# HDSC_HC32M120J6TB register map
Vendor: HDSC Co.,Ltd.; Series: ARMCM0P; File version: 1.0
CPU: CM0P r0p1, little endian, no MPU, no FPU, 4 interrupt priority bits
Registers are 32-bit, read-write, reset 0x0 unless marked. A register's access mark holds for its fields unless they carry their own. Offsets are from the block's base; [hi:lo] are bit positions; {n}, {i} and the like mark numbered series; 'fields as' and 'values as' point back to an identical list.

## ICG
Base 0x000000C0
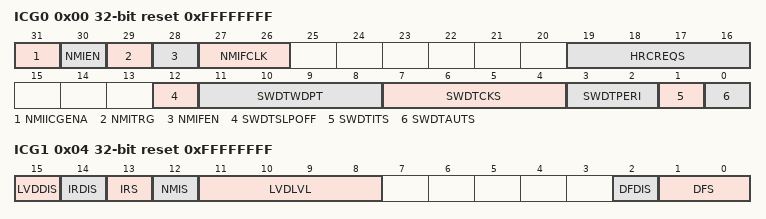
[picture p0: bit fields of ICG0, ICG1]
0x00 ICG0 ro reset 0xFFFFFFFF
  [31] NMIICGENA, [30] NMIEN, [29] NMITRG, [28] NMIFEN, [27:26] NMIFCLK, [19:16] HRCREQS, [12] SWDTSLPOFF, [11:8] SWDTWDPT, [7:4] SWDTCKS, [3:2] SWDTPERI, [1] SWDTITS, [0] SWDTAUTS
0x04 ICG1 ro reset 0xFFFFFFFF
  [15] LVDDIS, [14] IRDIS, [13] IRS, [12] NMIS, [11:8] LVDLVL, [2] DFDIS, [1:0] DFS
{0x0+4i} ICG{i} ro reset 0xFFFFFFFF (reset mask 0x0) (i=2..7)

## INTC
Base 0x40011000
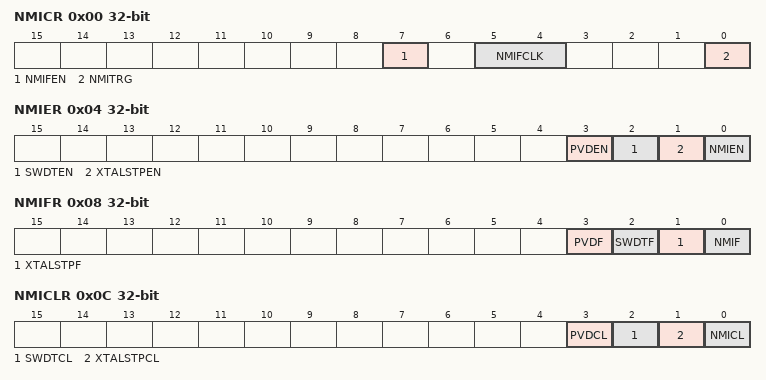
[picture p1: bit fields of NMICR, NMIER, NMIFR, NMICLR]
0x00 NMICR
  [7] NMIFEN, [5:4] NMIFCLK, [0] NMITRG
0x04 NMIER
  [3] PVDEN, [2] SWDTEN, [1] XTALSTPEN, [0] NMIEN
0x08 NMIFR ro
  [3] PVDF, [2] SWDTF, [1] XTALSTPF, [0] NMIF
0x0C NMICLR
  [3] PVDCL, [2] SWDTCL, [1] XTALSTPCL, [0] NMICL
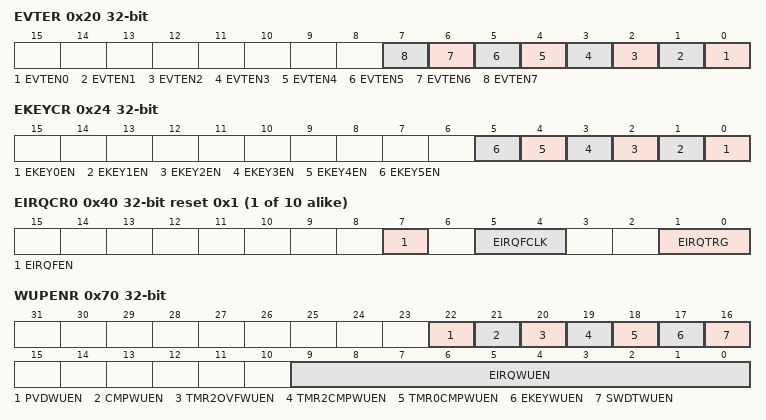
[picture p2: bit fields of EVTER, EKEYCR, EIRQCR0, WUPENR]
0x20 EVTER
  [n] EVTEN{n} (n=0..7)
0x24 EKEYCR
  [n] EKEY{n}EN (n=0..5)
0x3C FPRCR
  [7:0] FPRC
{0x40+4i} EIRQCR{i} reset 0x1 (i=0..9)
  [7] EIRQFEN, [5:4] EIRQFCLK, [1:0] EIRQTRG
0x70 WUPENR
  [22] PVDWUEN, [21] CMPWUEN, [20] TMR2OVFWUEN, [19] TMR2CMPWUEN, [18] TMR0CMPWUEN, [17] EKEYWUEN, [16] SWDTWUEN, [9:0] EIRQWUEN
0x74 EIRQFR
  [9:0] EIRQF
0x78 EIRQCLR
  [9:0] EIRQCL
{0x80+4i} ISELAR{i} (i=8..23)
  [3:0] ISEL
{0x80+4i} ISELBR{i} (i=24..31)
  [15:1] ISEL

## PORT
Base 0x40013800
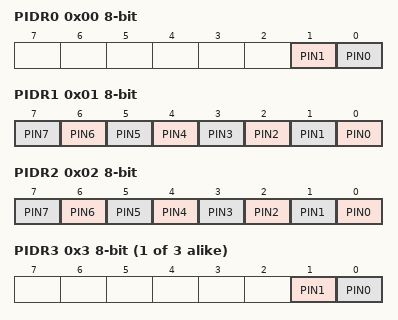
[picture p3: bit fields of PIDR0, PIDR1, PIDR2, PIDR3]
0x00 PIDR0 8-bit ro
  [1] PIN1, [0] PIN0
0x01 PIDR1 8-bit ro
  [n] PIN{n} (n=0..7)
0x02 PIDR2 8-bit ro
  [n] PIN{n} (n=0..7)
{0x0+i} PIDR{i} 8-bit ro (i=3..5)
  [1] PIN1, [0] PIN0
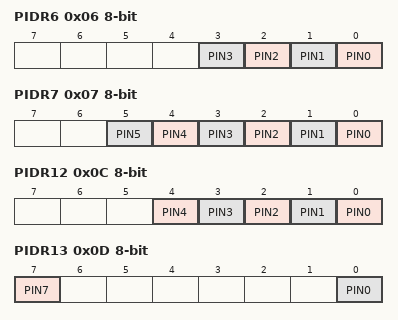
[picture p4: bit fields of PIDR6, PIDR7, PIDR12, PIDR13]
0x06 PIDR6 8-bit ro
  [n] PIN{n} (n=0..3)
0x07 PIDR7 8-bit ro
  [n] PIN{n} (n=0..5)
0x0C PIDR12 8-bit ro
  [n] PIN{n} (n=0..4)
0x0D PIDR13 8-bit ro
  [7] PIN7, [0] PIN0
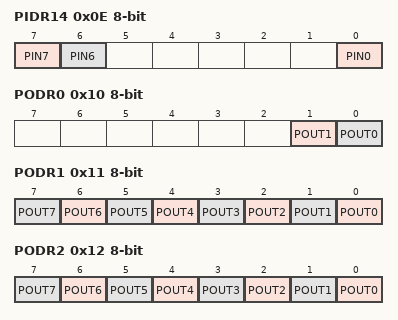
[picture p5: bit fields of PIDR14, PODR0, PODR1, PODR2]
0x0E PIDR14 8-bit ro
  [7] PIN7, [6] PIN6, [0] PIN0
0x10 PODR0 8-bit
  [1] POUT1, [0] POUT0
0x11 PODR1 8-bit
  [n] POUT{n} (n=0..7)
0x12 PODR2 8-bit
  [n] POUT{n} (n=0..7)
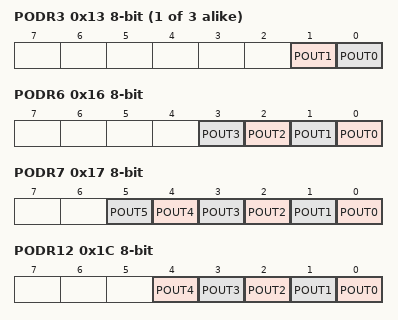
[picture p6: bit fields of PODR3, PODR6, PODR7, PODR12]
{0x10+i} PODR{i} 8-bit (i=3..5)
  [1] POUT1, [0] POUT0
0x16 PODR6 8-bit
  [n] POUT{n} (n=0..3)
0x17 PODR7 8-bit
  [n] POUT{n} (n=0..5)
0x1C PODR12 8-bit
  [n] POUT{n} (n=0..4)
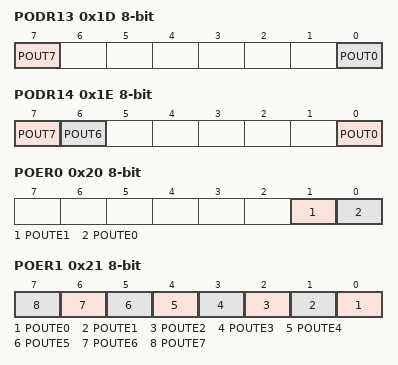
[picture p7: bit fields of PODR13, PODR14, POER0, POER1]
0x1D PODR13 8-bit
  [7] POUT7, [0] POUT0
0x1E PODR14 8-bit
  [7] POUT7, [6] POUT6, [0] POUT0
0x20 POER0 8-bit
  [1] POUTE1, [0] POUTE0
0x21 POER1 8-bit
  [n] POUTE{n} (n=0..7)
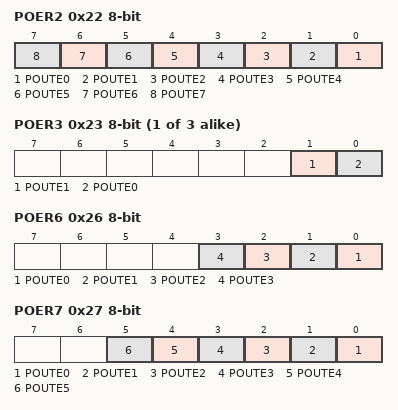
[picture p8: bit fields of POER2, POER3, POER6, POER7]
0x22 POER2 8-bit
  [n] POUTE{n} (n=0..7)
{0x20+i} POER{i} 8-bit (i=3..5)
  [1] POUTE1, [0] POUTE0
0x26 POER6 8-bit
  [n] POUTE{n} (n=0..3)
0x27 POER7 8-bit
  [n] POUTE{n} (n=0..5)
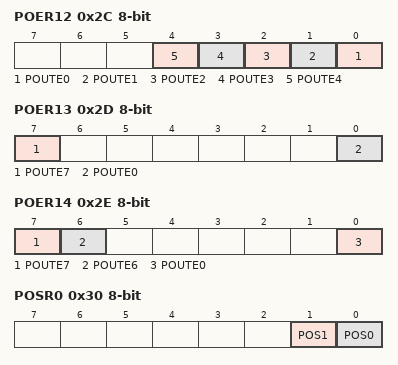
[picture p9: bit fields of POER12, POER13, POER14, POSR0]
0x2C POER12 8-bit
  [n] POUTE{n} (n=0..4)
0x2D POER13 8-bit
  [7] POUTE7, [0] POUTE0
0x2E POER14 8-bit
  [7] POUTE7, [6] POUTE6, [0] POUTE0
0x30 POSR0 8-bit wo
  [1] POS1, [0] POS0
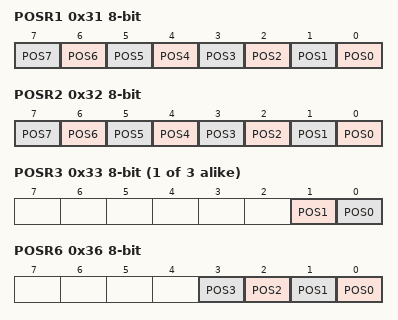
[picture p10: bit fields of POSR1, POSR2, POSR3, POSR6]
0x31 POSR1 8-bit wo
  [n] POS{n} (n=0..7)
0x32 POSR2 8-bit wo
  [n] POS{n} (n=0..7)
{0x30+i} POSR{i} 8-bit wo (i=3..5)
  [1] POS1, [0] POS0
0x36 POSR6 8-bit wo
  [n] POS{n} (n=0..3)
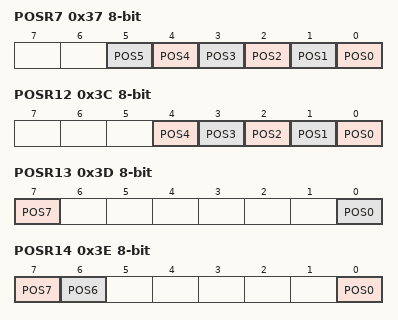
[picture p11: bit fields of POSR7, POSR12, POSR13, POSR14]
0x37 POSR7 8-bit wo
  [n] POS{n} (n=0..5)
0x3C POSR12 8-bit wo
  [n] POS{n} (n=0..4)
0x3D POSR13 8-bit wo
  [7] POS7, [0] POS0
0x3E POSR14 8-bit wo
  [7] POS7, [6] POS6, [0] POS0
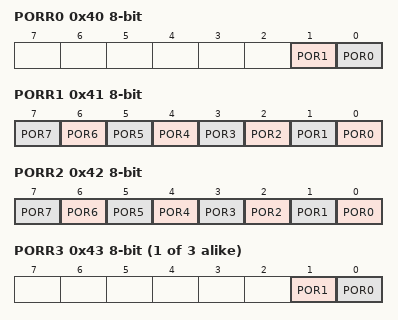
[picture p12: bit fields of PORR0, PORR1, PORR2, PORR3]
0x40 PORR0 8-bit wo
  [1] POR1, [0] POR0
0x41 PORR1 8-bit wo
  [n] POR{n} (n=0..7)
0x42 PORR2 8-bit wo
  [n] POR{n} (n=0..7)
{0x40+i} PORR{i} 8-bit wo (i=3..5)
  [1] POR1, [0] POR0
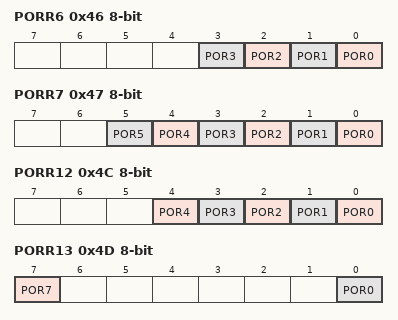
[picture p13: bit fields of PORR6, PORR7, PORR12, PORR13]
0x46 PORR6 8-bit wo
  [n] POR{n} (n=0..3)
0x47 PORR7 8-bit wo
  [n] POR{n} (n=0..5)
0x4C PORR12 8-bit wo
  [n] POR{n} (n=0..4)
0x4D PORR13 8-bit wo
  [7] POR7, [0] POR0
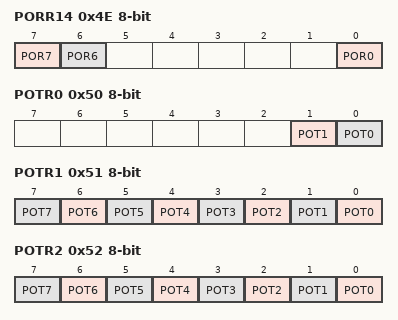
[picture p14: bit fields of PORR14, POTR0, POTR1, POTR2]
0x4E PORR14 8-bit wo
  [7] POR7, [6] POR6, [0] POR0
0x50 POTR0 8-bit wo
  [1] POT1, [0] POT0
0x51 POTR1 8-bit wo
  [n] POT{n} (n=0..7)
0x52 POTR2 8-bit wo
  [n] POT{n} (n=0..7)
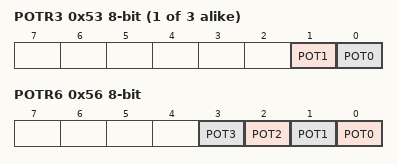
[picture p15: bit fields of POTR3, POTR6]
{0x50+i} POTR{i} 8-bit wo (i=3..5)
  [1] POT1, [0] POT0
0x56 POTR6 8-bit wo
  [n] POT{n} (n=0..3)
0x57 POTR7 8-bit wo
  [n] POT{n} (n=0..5)
0x5C POTR12 8-bit wo
  [n] POT{n} (n=0..4)
0x5D POTR13 8-bit wo
  [7] POT7, [0] POT0
0x5E POTR14 8-bit wo
  [7] POT7, [6] POT6, [0] POT0
0x400 PCR00 16-bit
  [14:12] FSEL, [11] INTE, [10] CINSEL, [9] INVE, [8] PIN ro, [6] PUU, [5] LTE, [4] DRV, [2] NOD, [1] POUTE, [0] POUT
0x402 PCR01 16-bit
  fields as PCR00
{0x3FC+2i} PCR{i} 16-bit (i=10..17)
  fields as PCR00
{0x3F8+2i} PCR{i} 16-bit (i=20..27)
  fields as PCR00
0x430 PCR30 16-bit
  fields as PCR00
0x432 PCR31 16-bit
  fields as PCR00
0x440 PCR40 16-bit
  fields as PCR00
0x442 PCR41 16-bit
  fields as PCR00
0x450 PCR50 16-bit
  fields as PCR00
0x452 PCR51 16-bit
  fields as PCR00
{0x3E8+2i} PCR{i} 16-bit (i=60..63)
  fields as PCR00
{0x3E4+2i} PCR{i} 16-bit (i=70..75)
  fields as PCR00
{0x3D0+2i} PCR{i} 16-bit (i=120..124)
  fields as PCR00
0x4D0 PCR130 16-bit
  fields as PCR00
0x4DE PCR137 16-bit
  fields as PCR00
0x4E0 PCR140 16-bit
  fields as PCR00
0x4EC PCR146 16-bit
  fields as PCR00
0x4EE PCR147 16-bit
  fields as PCR00
0x500 PSPCR 16-bit reset 0x3
  [1:0] SPFE
0x504 PCCR 16-bit reset 0x4000
  [15:14] RDWT
0x506 PINAER 16-bit
  [14] PINAE14, [13] PINAE13, [12] PINAE12, [n] PINAE{n} (n=0..7)
0x508 PWPR 16-bit
  [15:8] WP wo, [0] WE
